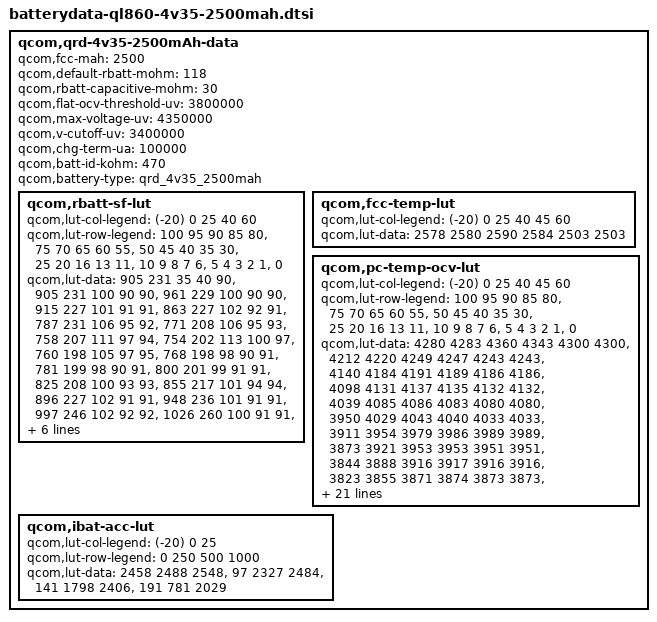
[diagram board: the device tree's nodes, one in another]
/* Copyright (c) 2013, The Linux Foundation. All rights reserved.
 *
 * This program is free software; you can redistribute it and/or modify
 * it under the terms of the GNU General Public License version 2 and
 * only version 2 as published by the Free Software Foundation.
 *
 * This program is distributed in the hope that it will be useful,
 * but WITHOUT ANY WARRANTY; without even the implied warranty of
 * MERCHANTABILITY or FITNESS FOR A PARTICULAR PURPOSE.  See the
 * GNU General Public License for more details.
 */
/* xiongzuan add battery information capacity and rbatt by 20150613 begin*/
qcom,qrd-4v35-2500mAh-data {
	qcom,fcc-mah = <2500>;
	qcom,default-rbatt-mohm = <118>;
	qcom,rbatt-capacitive-mohm = <30>;
	qcom,flat-ocv-threshold-uv = <3800000>;
	qcom,max-voltage-uv = <4350000>;
	qcom,v-cutoff-uv = <3400000>;
	qcom,chg-term-ua = <100000>;
	qcom,batt-id-kohm = <470>;
	qcom,battery-type = "qrd_4v35_2500mah";

	qcom,rbatt-sf-lut {
		qcom,lut-col-legend = <(-20) 0 25 40 60>;
		qcom,lut-row-legend = <100 95 90 85 80>,
				<75 70 65 60 55>,
				<50 45 40 35 30>,
				<25 20 16 13 11>,
				<10 9 8 7 6>,
				<5 4 3 2 1>,
				<0>;
		qcom,lut-data = 
                                                        <905  231  35  40  90>,  
						        <905  231  100  90  90>,  
						        <961  229  100  90  90>, 
						        <915  227  101  91  91>, 
						        <863  227  102  92  91>, 
						        <787  231  106  95  92>,  
						        <771  208  106  95  93>,  
						        <758  207  111  97  94>,  
						        <754  202  113  100  97>,  
						        <760  198  105  97  95>,  
						        <768  198  98  90  91>, 
						        <781  199  98  90  91>,  
						        <800  201  99  91  91>,  
						        <825  208  100  93  93>,  
						        <855  217  101  94  94>,  
						        <896  227  102  91  91>, 
						        <948  236  101  91  91>, 
						        <997  246  102  92  92>,  
						        <1026  260  100  91  91>,  
						        <977  259  100  91  91>,  
						        <1005  265  101  92  92>,  
						        <1035  275  102  93  93>,  
						        <1069  287  103  94  94>,  
						        <1108  300  106  96  95>,  
						        <1190  312  109  97  96>,  
						        <1371  323  108  96  94>,  
						        <1641  339  107  94  93>,  
						        <2086  371  109  96  95>,  
						        <3035  421  115  102  99>,  
						        <15561  627  138  124  112>,  
						        <21302  697  367  235  160>;
	};

	qcom,fcc-temp-lut {
		qcom,lut-col-legend = <(-20) 0 25 40 45 60>;
		qcom,lut-data = <2578 2580 2590 2584 2503 2503>;
	};

	qcom,pc-temp-ocv-lut {
		qcom,lut-col-legend = <(-20) 0 25 40 45 60>;
		qcom,lut-row-legend = <100 95 90 85 80>,
				<75 70 65 60 55>,
				<50 45 40 35 30>,
				<25 20 16 13 11>,
				<10 9 8 7 6>,
				<5 4 3 2 1>,
				<0>;
		qcom,lut-data = 
				<4280  4283  4360  4343  4300  4300>,  
				<4212  4220  4249  4247  4243  4243>,
				<4140  4184  4191  4189  4186  4186>,
				<4098  4131  4137  4135  4132  4132>,  
				<4039  4085  4086  4083  4080  4080>, 
				<3950  4029  4043  4040  4033  4033>,  
				<3911  3954  3979  3986  3989  3989>,  
				<3873  3921  3953  3953  3951  3951>, 
				<3844  3888  3916  3917  3916  3916>,  
				<3823  3855  3871  3874  3873  3873>,  
				<3806  3828  3836  3836  3835  3835>,  
				<3791  3806  3813  3813  3812  3812>,  
				<3777  3789  3790  3790  3794  3794>,//40
				<3763  3778  3772  3775  3770  3774>, 
				<3748  3757  3757  3759  3756  3756>,//30
				<3733  3743  3741  3742  3739  3739>,  
				<3698  3726  3720  3721  3722  3725>,//20
				<3652  3700  3699  3699  3693  3693>,
				<3612  3684  3670  3668  3657  3657>,//13
				<3576  3674  3666  3664  3652  3652>,
				<3552  3670  3663  3660  3650  3652>,//10
				<3524  3664  3659  3658  3648  3648>,
				<3490  3659  3655  3654  3644  3648>,
				<3452  3651  3650  3649  3638  3638>,
				<3403  3638  3645  3638  3626  3626>,
				<3343  3612  3618  3610  3590  3590>,
				<3263  3570  3570  3559  3540  3540>,
				<3189  3509  3505  3494  3474  3474>,
				<3126  3422  3417  3405  3385  3385>,
				<3058  3391  3386  3373  3354  3354>,
				<3000  3300  3300  3300  3300  3300>;
	};
	qcom,ibat-acc-lut {
		qcom,lut-col-legend = <(-20) 0 25>;
		qcom,lut-row-legend = <0 250 500 1000>;
		qcom,lut-data = <2458 2488 2548>,
				        <97 2327 2484>,
				        <141 1798 2406>,
			         	<191 781 2029>;
 };
};
/* xiongzuan add battery information capacity and rbatt by 20150613 end*/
